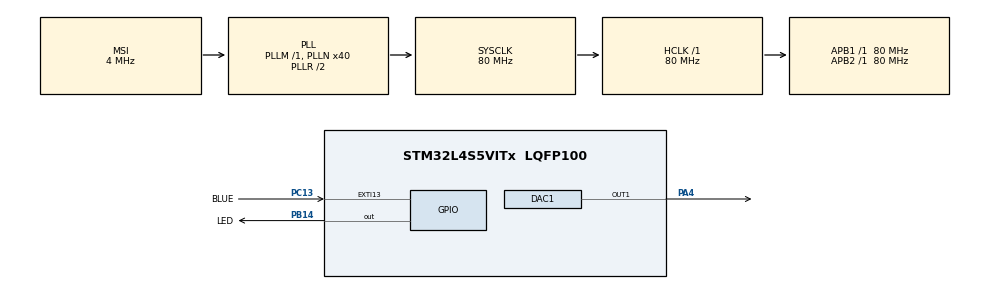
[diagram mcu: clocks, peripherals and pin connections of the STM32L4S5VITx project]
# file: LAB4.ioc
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DAC1.DAC_Trigger-DAC_OUT1=DAC_TRIGGER_T2_TRGO
Dma.DAC1_CH1.0.Direction=DMA_MEMORY_TO_PERIPH
Dma.DAC1_CH1.0.EventEnable=DISABLE
Dma.DAC1_CH1.0.Instance=DMA1_Channel1
Dma.DAC1_CH1.0.MemDataAlignment=DMA_MDATAALIGN_BYTE
Dma.DAC1_CH1.0.MemInc=DMA_MINC_ENABLE
Dma.DAC1_CH1.0.Mode=DMA_CIRCULAR
Dma.DAC1_CH1.0.PeriphDataAlignment=DMA_PDATAALIGN_BYTE
Dma.DAC1_CH1.0.PeriphInc=DMA_PINC_DISABLE
Dma.DAC1_CH1.0.Polarity=HAL_DMAMUX_REQUEST_GEN_RISING
Dma.DAC1_CH1.0.Priority=DMA_PRIORITY_LOW
Dma.DAC1_CH1.0.RequestNumber=1
Dma.DAC1_CH1.0.SignalID=NONE
Dma.DAC1_CH1.0.SyncEnable=DISABLE
Dma.DAC1_CH1.0.SyncPolarity=HAL_DMAMUX_SYNC_NO_EVENT
Dma.DAC1_CH1.0.SyncRequestNumber=1
Dma.DAC1_CH1.0.SyncSignalID=NONE
Dma.Request0=DAC1_CH1
Mcu.Family=STM32L4
Mcu.Name=STM32L4S5VITx
Mcu.Package=LQFP100
NVIC.DMA1_Channel1_IRQn=true\:0\:0\:false\:false\:true\:false\:true\:true
NVIC.EXTI15_10_IRQn=true\:0\:0\:false\:false\:true\:true\:true\:true
NVIC.PriorityGroup=NVIC_PRIORITYGROUP_4
NVIC.TIM2_IRQn=true\:0\:0\:false\:false\:true\:true\:true\:true
PA13\ (JTMS/SWDIO).Signal=SYS_JTMS-SWDIO
PA4.Signal=COMP_DAC11_group
PB14.GPIO_Label=LED
PB14.Signal=GPIO_Output
PB3\ (JTDO/TRACESWO).Signal=SYS_JTDO-SWO
PC13.GPIO_Label=BLUE
PC13.Signal=GPXTI13
ProjectManager.HeapSize=0x200
ProjectManager.StackSize=0x400
ProjectManager.TargetToolchain=STM32CubeIDE
RCC.ADCFreq_Value=48000000
RCC.AHBFreq_Value=80000000
RCC.APB1Freq_Value=80000000
RCC.APB1TimFreq_Value=80000000
RCC.APB2Freq_Value=80000000
RCC.APB2TimFreq_Value=80000000
RCC.CortexFreq_Value=80000000
RCC.HCLKFreq_Value=80000000
RCC.HSE_VALUE=8000000
RCC.HSI48_VALUE=48000000
RCC.HSI_VALUE=16000000
RCC.LSE_VALUE=32768
RCC.MSI_VALUE=4000000
RCC.PLLN=40
RCC.PLLSAI1N=24
RCC.SYSCLKFreq_VALUE=80000000
RCC.SYSCLKSource=RCC_SYSCLKSOURCE_PLLCLK
RCC.USBFreq_Value=48000000
RCC.VCOOutputFreq_Value=160000000
SH.COMP_DAC11_group.0=DAC1_OUT1,DAC_OUT1
TIM2.Period=1814
TIM2.Prescaler=0
TIM2.TIM_MasterOutputTrigger=TIM_TRGO_UPDATE
VP_TIM2_VS_ClockSourceINT.Mode=Internal
board=B-L4S5I-IOT01A

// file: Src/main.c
/* USER CODE BEGIN Header */
/**
  ******************************************************************************
  * @file           : main.c
  * @brief          : Main program body
  ******************************************************************************
  * @attention
  *
  * Copyright (c) 2022 STMicroelectronics.
  * All rights reserved.
  *
  * This software is licensed under terms that can be found in the LICENSE file
  * in the root directory of this software component.
  * If no LICENSE file comes with this software, it is provided AS-IS.
  *
  ******************************************************************************
  */
/* USER CODE END Header */
#include "main.h"

/* USER CODE BEGIN Includes */
#define ARM_MATH_CM4
#include "arm_math.h"

/* USER CODE END Includes */

DAC_HandleTypeDef hdac1;
DMA_HandleTypeDef hdma_dac1_ch1;

TIM_HandleTypeDef htim2;

void SystemClock_Config(void);
static void MX_GPIO_Init(void);
static void MX_DMA_Init(void);
static void MX_DAC1_Init(void);
static void MX_TIM2_Init(void);

/* USER CODE BEGIN 0 */
void HAL_GPIO_EXTI_Callback (uint16_t GPIO_Pin);
// void HAL_TIM_PeriodElapsedCallback (TIM_HandleTypeDef * htim);

uint8_t arrayOne[22];
uint8_t arrayTwo[44];
uint8_t arrayThree[66];
int indexCounterOne = 0;
int indexCounterTwo = 0;
int indexCounterThree = 0;
int callbackCounter = 0;
int toggleCounter = 0;

/* USER CODE END 0 */

int main(void)
{
  /* USER CODE BEGIN 1 */
	//int temp = 9;  // test
	for (float i = 0; i < 6.284 ; i = i + 0.29){

		uint8_t conv = (uint8_t)((arm_sin_f32(i) * 127) + 127);
		arrayOne[indexCounterOne] = conv;
		indexCounterOne++;
	}

	for (float i = 0; i < 6.284 ; i = i + 0.143){

		uint8_t conv = (uint8_t)((arm_sin_f32(i) * 127) + 127);
		arrayTwo[indexCounterTwo] = conv;
		indexCounterTwo++;
	}

	for (float i = 0; i < 6.284 ; i = i + 0.095){

		uint8_t conv = (uint8_t)((arm_sin_f32(i) * 127) + 127);
		arrayThree[indexCounterThree] = conv;
		indexCounterThree++;
	}
	//temp = arrayOne[15];  // test

  /* USER CODE END 1 */

  /* MCU Configuration--------------------------------------------------------*/

  /* Reset of all peripherals, Initializes the Flash interface and the Systick. */
  HAL_Init();

  /* USER CODE BEGIN Init */

  //HAL_GPIO_EXTI_Callback (BLUE_Pin);			// WORKS WITHOUT CALLING

  /* USER CODE END Init */

  /* Configure the system clock */
  SystemClock_Config();

  /* Initialize all configured peripherals */
  MX_GPIO_Init();
  MX_DMA_Init();
  MX_DAC1_Init();
  MX_TIM2_Init();
  /* USER CODE BEGIN 2 */

  // Start timer
  //HAL_TIM_Base_Start_IT(&htim2);
  //HAL_DAC_Start(&hdac1,DAC_CHANNEL_1);

  //HAL_DAC_Start_DMA(&hdac1, DAC_CHANNEL_1, (uint32_t*)arrayOne, 8, DAC_ALIGN_8B_R);

  HAL_TIM_Base_Start(&htim2);
  //HAL_TIM_Base_Start_DMA(&htim2, (uint32_t*)arrayOne, 32);
  HAL_DAC_Start_DMA(&hdac1, DAC_CHANNEL_1, (uint32_t*)arrayOne, 22, DAC_ALIGN_12B_R);

  /* USER CODE END 2 */

  /* Infinite loop */
  while (1)
  {

  }
}

void SystemClock_Config(void)
{
  RCC_OscInitTypeDef RCC_OscInitStruct = {0};
  RCC_ClkInitTypeDef RCC_ClkInitStruct = {0};

  /** Configure the main internal regulator output voltage
  */
  if (HAL_PWREx_ControlVoltageScaling(PWR_REGULATOR_VOLTAGE_SCALE1) != HAL_OK)
  {
    Error_Handler();
  }

  /** Initializes the RCC Oscillators according to the specified parameters
  * in the RCC_OscInitTypeDef structure.
  */
  RCC_OscInitStruct.OscillatorType = RCC_OSCILLATORTYPE_MSI;
  RCC_OscInitStruct.MSIState = RCC_MSI_ON;
  RCC_OscInitStruct.MSICalibrationValue = 0;
  RCC_OscInitStruct.MSIClockRange = RCC_MSIRANGE_6;
  RCC_OscInitStruct.PLL.PLLState = RCC_PLL_ON;
  RCC_OscInitStruct.PLL.PLLSource = RCC_PLLSOURCE_MSI;
  RCC_OscInitStruct.PLL.PLLM = 1;
  RCC_OscInitStruct.PLL.PLLN = 40;
  RCC_OscInitStruct.PLL.PLLP = RCC_PLLP_DIV2;
  RCC_OscInitStruct.PLL.PLLQ = RCC_PLLQ_DIV2;
  RCC_OscInitStruct.PLL.PLLR = RCC_PLLR_DIV2;
  if (HAL_RCC_OscConfig(&RCC_OscInitStruct) != HAL_OK)
  {
    Error_Handler();
  }

  /** Initializes the CPU, AHB and APB buses clocks
  */
  RCC_ClkInitStruct.ClockType = RCC_CLOCKTYPE_HCLK|RCC_CLOCKTYPE_SYSCLK
                              |RCC_CLOCKTYPE_PCLK1|RCC_CLOCKTYPE_PCLK2;
  RCC_ClkInitStruct.SYSCLKSource = RCC_SYSCLKSOURCE_PLLCLK;
  RCC_ClkInitStruct.AHBCLKDivider = RCC_SYSCLK_DIV1;
  RCC_ClkInitStruct.APB1CLKDivider = RCC_HCLK_DIV1;
  RCC_ClkInitStruct.APB2CLKDivider = RCC_HCLK_DIV1;

  if (HAL_RCC_ClockConfig(&RCC_ClkInitStruct, FLASH_LATENCY_3) != HAL_OK)
  {
    Error_Handler();
  }
}

static void MX_DAC1_Init(void)
{

  DAC_ChannelConfTypeDef sConfig = {0};

  /** DAC Initialization
  */
  hdac1.Instance = DAC1;
  if (HAL_DAC_Init(&hdac1) != HAL_OK)
  {
    Error_Handler();
  }

  /** DAC channel OUT1 config
  */
  sConfig.DAC_SampleAndHold = DAC_SAMPLEANDHOLD_DISABLE;
  sConfig.DAC_Trigger = DAC_TRIGGER_T2_TRGO;
  sConfig.DAC_HighFrequency = DAC_HIGH_FREQUENCY_INTERFACE_MODE_ABOVE_80MHZ;
  sConfig.DAC_OutputBuffer = DAC_OUTPUTBUFFER_ENABLE;
  sConfig.DAC_ConnectOnChipPeripheral = DAC_CHIPCONNECT_DISABLE;
  sConfig.DAC_UserTrimming = DAC_TRIMMING_FACTORY;
  if (HAL_DAC_ConfigChannel(&hdac1, &sConfig, DAC_CHANNEL_1) != HAL_OK)
  {
    Error_Handler();
  }

}

static void MX_TIM2_Init(void)
{

  TIM_ClockConfigTypeDef sClockSourceConfig = {0};
  TIM_MasterConfigTypeDef sMasterConfig = {0};

  htim2.Instance = TIM2;
  htim2.Init.Prescaler = 0;
  htim2.Init.CounterMode = TIM_COUNTERMODE_UP;
  htim2.Init.Period = 1814;
  htim2.Init.ClockDivision = TIM_CLOCKDIVISION_DIV1;
  htim2.Init.AutoReloadPreload = TIM_AUTORELOAD_PRELOAD_DISABLE;
  if (HAL_TIM_Base_Init(&htim2) != HAL_OK)
  {
    Error_Handler();
  }
  sClockSourceConfig.ClockSource = TIM_CLOCKSOURCE_INTERNAL;
  if (HAL_TIM_ConfigClockSource(&htim2, &sClockSourceConfig) != HAL_OK)
  {
    Error_Handler();
  }
  sMasterConfig.MasterOutputTrigger = TIM_TRGO_UPDATE;
  sMasterConfig.MasterSlaveMode = TIM_MASTERSLAVEMODE_DISABLE;
  if (HAL_TIMEx_MasterConfigSynchronization(&htim2, &sMasterConfig) != HAL_OK)
  {
    Error_Handler();
  }

}

static void MX_DMA_Init(void)
{

  /* DMA controller clock enable */
  __HAL_RCC_DMAMUX1_CLK_ENABLE();
  __HAL_RCC_DMA1_CLK_ENABLE();

  /* DMA interrupt init */
  /* DMA1_Channel1_IRQn interrupt configuration */
  HAL_NVIC_SetPriority(DMA1_Channel1_IRQn, 0, 0);
  HAL_NVIC_EnableIRQ(DMA1_Channel1_IRQn);

}

static void MX_GPIO_Init(void)
{
  GPIO_InitTypeDef GPIO_InitStruct = {0};

  /* GPIO Ports Clock Enable */
  __HAL_RCC_GPIOC_CLK_ENABLE();
  __HAL_RCC_GPIOA_CLK_ENABLE();
  __HAL_RCC_GPIOB_CLK_ENABLE();

  /*Configure GPIO pin Output Level */
  HAL_GPIO_WritePin(LED_GPIO_Port, LED_Pin, GPIO_PIN_RESET);

  /*Configure GPIO pin : BLUE_Pin */
  GPIO_InitStruct.Pin = BLUE_Pin;
  GPIO_InitStruct.Mode = GPIO_MODE_IT_RISING;
  GPIO_InitStruct.Pull = GPIO_NOPULL;
  HAL_GPIO_Init(BLUE_GPIO_Port, &GPIO_InitStruct);

  /*Configure GPIO pin : LED_Pin */
  GPIO_InitStruct.Pin = LED_Pin;
  GPIO_InitStruct.Mode = GPIO_MODE_OUTPUT_PP;
  GPIO_InitStruct.Pull = GPIO_NOPULL;
  GPIO_InitStruct.Speed = GPIO_SPEED_FREQ_LOW;
  HAL_GPIO_Init(LED_GPIO_Port, &GPIO_InitStruct);

  /* EXTI interrupt init*/
  HAL_NVIC_SetPriority(EXTI15_10_IRQn, 0, 0);
  HAL_NVIC_EnableIRQ(EXTI15_10_IRQn);

}

/* USER CODE BEGIN 4 */

void HAL_GPIO_EXTI_Callback (uint16_t GPIO_Pin) {
	toggleCounter++;
	if(toggleCounter > 3) {
		toggleCounter = 1;
	}
	if(GPIO_Pin == BLUE_Pin) {
		if(HAL_GPIO_ReadPin(GPIOB, LED_Pin) == GPIO_PIN_SET) {
			HAL_GPIO_WritePin(GPIOB, LED_Pin, GPIO_PIN_RESET);
		} else {
			HAL_GPIO_WritePin(GPIOB, LED_Pin, GPIO_PIN_SET);
		}
	}

	if(toggleCounter == 1) {
//		for (float i = 0; i < 6.284 ; i = i + 0.29){
//
//			if(indexCounter > 21) {
//				indexCounter = 0;
//			}
//			uint16_t conv = (uint16_t)((arm_sin_f32(i) * 1500) + 1500);
//			arrayOne[indexCounter] = conv;
//			indexCounter++;
//		}

		HAL_DAC_Stop_DMA(&hdac1, DAC_CHANNEL_1);
		HAL_DAC_Start_DMA(&hdac1, DAC_CHANNEL_1, &arrayTwo, 44, DAC_ALIGN_8B_R);
	} else 	if(toggleCounter == 2) {
//		for (float i = 0; i < 6.284 ; i = i + 0.29){
//
//			if(indexCounter > 21) {
//				indexCounter = 0;
//			}
//			uint16_t conv = (uint16_t)((arm_sin_f32(i) * 2000) + 2000);
//			arrayOne[indexCounter] = conv;
//			indexCounter++;
//		}
		HAL_DAC_Stop_DMA(&hdac1, DAC_CHANNEL_1);
		HAL_DAC_Start_DMA(&hdac1, DAC_CHANNEL_1, &arrayThree, 66, DAC_ALIGN_8B_R);
	} else 	if(toggleCounter == 3) {
//		for (float i = 0; i < 6.284 ; i = i + 0.29){
//
//			if(indexCounter > 21) {
//				indexCounter = 0;
//			}
//
//			uint16_t conv = (uint16_t)((arm_sin_f32(i) * 630) + 630);
//			arrayOne[indexCounter] = conv;
//			indexCounter++;
//		}
		HAL_DAC_Stop_DMA(&hdac1, DAC_CHANNEL_1);
		HAL_DAC_Start_DMA(&hdac1, DAC_CHANNEL_1, &arrayOne, 22, DAC_ALIGN_8B_R);
	}
}

//void HAL_TIM_PeriodElapsedCallback (TIM_HandleTypeDef * htim) {
//	if(callbackCounter > 21) {
//		callbackCounter = 0;
//	}
//	uint8_t tone = (uint8_t) arrayOne[callbackCounter];
//	HAL_DAC_SetValue(&hdac1, DAC_CHANNEL_1, DAC_ALIGN_8B_R, tone);
//	callbackCounter++;
//
//
//}

/* USER CODE END 4 */

void Error_Handler(void)
{
  __disable_irq();
  while (1)
  {
  }
}
